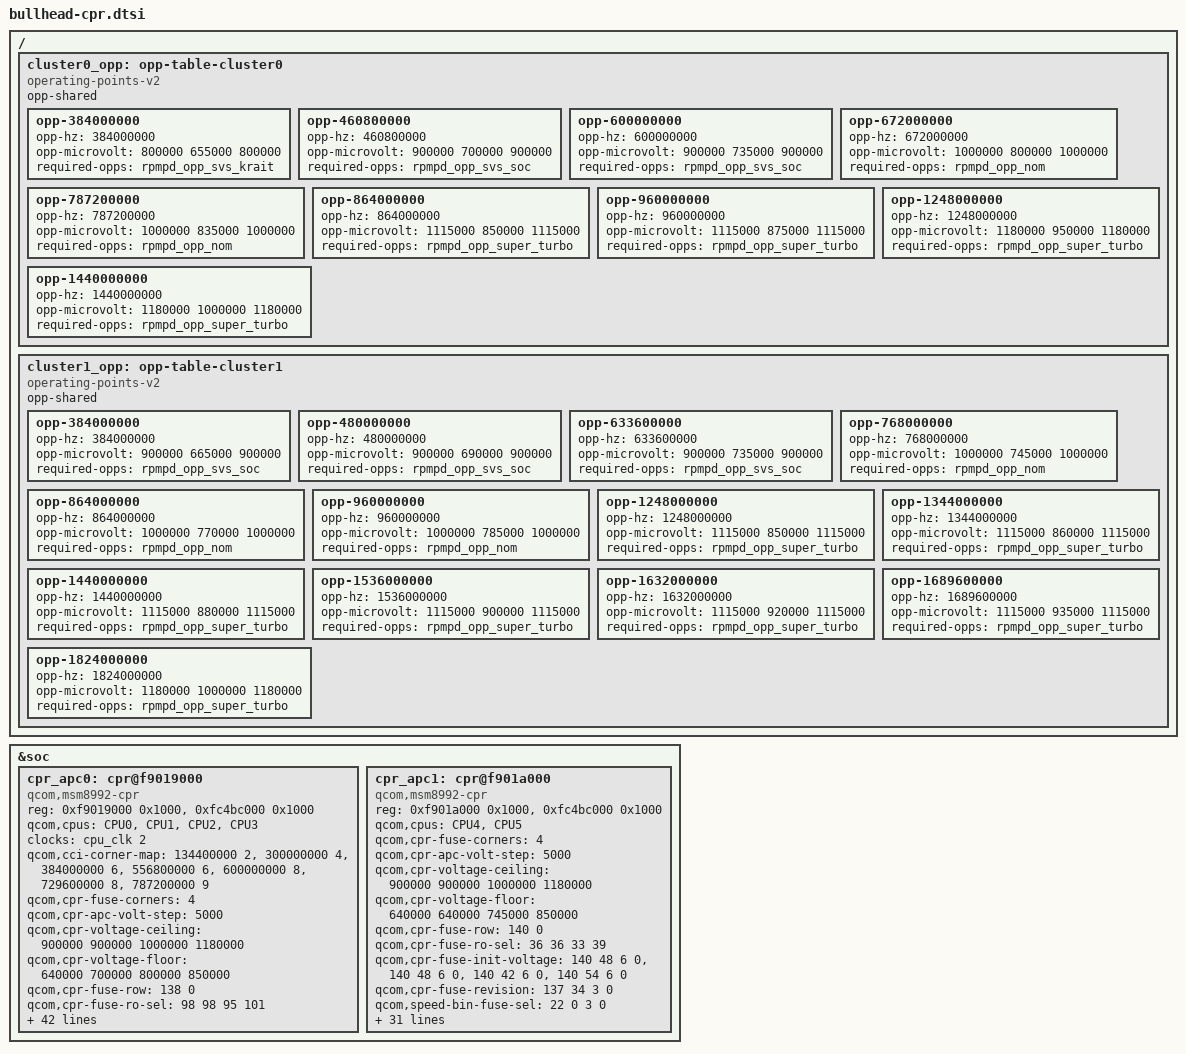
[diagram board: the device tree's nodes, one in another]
// SPDX-License-Identifier: GPL-2.0-only
/* Generated by tools/cpr/gen-cpr-dtsi.py from the 3.10 msm8992-regulator.dtsi */

&soc {
	cpr_apc0: cpr@f9019000 {
		compatible = "qcom,msm8992-cpr";
		reg = <0xf9019000 0x1000>, <0xfc4bc000 0x1000>;
		reg-names = "rbcpr", "efuse";
		qcom,cpus = <&CPU0>, <&CPU1>, <&CPU2>, <&CPU3>;
		clocks = <&cpu_clk 2>;
		clock-names = "cci";
		qcom,cci-corner-map = <134400000 2>, <300000000 4>,
			<384000000 6>, <556800000 6>, <600000000 8>,
			<729600000 8>, <787200000 9>;
		qcom,cpr-fuse-corners = <4>;
		qcom,cpr-apc-volt-step = <5000>;
		qcom,cpr-voltage-ceiling = <900000 900000 1000000 1180000>;
		qcom,cpr-voltage-floor = <640000 700000  800000  850000>;
		qcom,cpr-fuse-row = <138 0>;
		qcom,cpr-fuse-ro-sel = <98 98 95 101>;
		qcom,cpr-fuse-init-voltage = <139 46 6 0>,
			<139 46 6 0>,
			<139 40 6 0>,
			<139 52 6 0>;
		qcom,cpr-fuse-revision = <137 34 3 0>;
		qcom,speed-bin-fuse-sel = <22 56 2 0>;
		qcom,cpr-fuse-redun-sel = <62 48 3 1 0>;
		qcom,cpr-init-voltage-ref = <900000 900000 1000000 1230000>;
		qcom,cpr-init-voltage-step = <10000>;
		qcom,cpr-corner-map = <1 1 2 2 3 3 4 4 4 4>;
		qcom,cpr-voltage-ceiling-override = <0xFFFFFFFF 0  800000  800000  900000  900000
			1000000 1000000 1115000 1115000
			1180000 1180000>;
		qcom,cpr-voltage-floor-override = <0xFFFFFFFF 0  640000  655000  700000  735000
			800000  835000  850000  875000
			950000 1000000>;
		qcom,cpr-fuse-version-map = <0 0xffffffff 0 0 0 0 0>,
			<0 0xffffffff 1 0 0 0 0>,
			<0 0xffffffff 2 0 0 0 0>,
			<0 0xffffffff 3 0 0 0 0>,
			<0 0xffffffff 4 0 0 0 0>,
			<1 0xffffffff 0 0 0 0 0>,
			<1 0xffffffff 1 0 0 0 0>,
			<1 0xffffffff 2 0 0 0 0>,
			<1 0xffffffff 3 0 0 0 0>,
			<1 0xffffffff 4 0 0 0 0>;
		qcom,cpr-init-voltage-adjustment = <0 0 0 0>,
			<0 (-15000) (-35000) 35000>,
			<0 (-15000) (-35000) 35000>,
			<0 (-15000) (-25000) (-15000)>,
			<0 (-15000) (-25000) (-60000)>,
			<0 0 0 0>,
			<0 (-15000) (-35000) 95000>,
			<0 (-15000) (-35000) 95000>,
			<0 (-15000) (-25000) 45000>,
			<0 (-15000) (-25000) 0>;
		qcom,cpr-voltage-scaling-factor-max = <0 0 2000 2000>;
		qcom,cpr-corner-frequency-map = <1   300000000>,
			<2   384000000>,
			<3   460800000>,
			<4   600000000>,
			<5   672000000>,
			<6   787200000>,
			<7   864000000>,
			<8   960000000>,
			<9  1248000000>,
			<10 1440000000>;
		qcom,cpr-speed-bin-max-corners = <0 0 2 4 6 9>,
			<1 0 2 4 6 10>;
		qcom,cpr-scaled-init-voltage-as-ceiling;
	};
};

/ {
	cluster0_opp: opp-table-cluster0 {
		compatible = "operating-points-v2";
		opp-shared;

		opp-384000000 {
			opp-hz = /bits/ 64 <384000000>;
			opp-microvolt = <800000 655000 800000>;
			required-opps = <&rpmpd_opp_svs_krait>;
		};
		opp-460800000 {
			opp-hz = /bits/ 64 <460800000>;
			opp-microvolt = <900000 700000 900000>;
			required-opps = <&rpmpd_opp_svs_soc>;
		};
		opp-600000000 {
			opp-hz = /bits/ 64 <600000000>;
			opp-microvolt = <900000 735000 900000>;
			required-opps = <&rpmpd_opp_svs_soc>;
		};
		opp-672000000 {
			opp-hz = /bits/ 64 <672000000>;
			opp-microvolt = <1000000 800000 1000000>;
			required-opps = <&rpmpd_opp_nom>;
		};
		opp-787200000 {
			opp-hz = /bits/ 64 <787200000>;
			opp-microvolt = <1000000 835000 1000000>;
			required-opps = <&rpmpd_opp_nom>;
		};
		opp-864000000 {
			opp-hz = /bits/ 64 <864000000>;
			opp-microvolt = <1115000 850000 1115000>;
			required-opps = <&rpmpd_opp_super_turbo>;
		};
		opp-960000000 {
			opp-hz = /bits/ 64 <960000000>;
			opp-microvolt = <1115000 875000 1115000>;
			required-opps = <&rpmpd_opp_super_turbo>;
		};
		opp-1248000000 {
			opp-hz = /bits/ 64 <1248000000>;
			opp-microvolt = <1180000 950000 1180000>;
			required-opps = <&rpmpd_opp_super_turbo>;
		};
		opp-1440000000 {
			opp-hz = /bits/ 64 <1440000000>;
			opp-microvolt = <1180000 1000000 1180000>;
			required-opps = <&rpmpd_opp_super_turbo>;
		};
	};
};

&soc {
	cpr_apc1: cpr@f901a000 {
		compatible = "qcom,msm8992-cpr";
		reg = <0xf901a000 0x1000>, <0xfc4bc000 0x1000>;
		reg-names = "rbcpr", "efuse";
		qcom,cpus = <&CPU4>, <&CPU5>;
		qcom,cpr-fuse-corners = <4>;
		qcom,cpr-apc-volt-step = <5000>;
		qcom,cpr-voltage-ceiling = <900000 900000 1000000 1180000>;
		qcom,cpr-voltage-floor = <640000 640000  745000  850000>;
		qcom,cpr-fuse-row = <140 0>;
		qcom,cpr-fuse-ro-sel = <36 36 33 39>;
		qcom,cpr-fuse-init-voltage = <140 48 6 0>,
			<140 48 6 0>,
			<140 42 6 0>,
			<140 54 6 0>;
		qcom,cpr-fuse-revision = <137 34 3 0>;
		qcom,speed-bin-fuse-sel = <22 0 3 0>;
		qcom,cpr-fuse-redun-sel = <62 48 3 1 0>;
		qcom,cpr-init-voltage-ref = <900000 900000 1000000 1230000>;
		qcom,cpr-init-voltage-step = <10000>;
		qcom,cpr-corner-map = <1 2 2 2 2 3 3 3 4 4 4 4 4 4 4>;
		qcom,cpr-voltage-ceiling-override = <0xFFFFFFFF 0  900000  900000  900000  900000
			900000 1000000 1000000 1000000
			1115000 1115000 1115000 1115000
			1115000 1115000 1180000>;
		qcom,cpr-voltage-floor-override = <0xFFFFFFFF 0  640000  640000  665000  690000
			735000  745000  770000  785000
			850000  860000  880000  900000
			920000  935000 1000000>;
		qcom,cpr-fuse-version-map = <0xffffffff 0xffffffff 0 4 4 4 4>,
			<0xffffffff 0xffffffff 1 4 4 4 4>,
			<0xffffffff 0xffffffff 2 4 4 4 4>,
			<0xffffffff 0xffffffff 3 2 2 2 2>,
			<0xffffffff 0xffffffff 4 2 2 2 2>;
		qcom,cpr-init-voltage-adjustment = <0 0 0 0>,
			<0 0 (-25000) (-25000)>,
			<0 0 30000 (-5000)>,
			<30000 30000 (-20000) (-20000)>,
			<30000 30000 (-20000) (-20000)>;
		qcom,cpr-voltage-scaling-factor-max = <0 0 2000 2000>;
		qcom,cpr-corner-frequency-map = <1   300000000>, /* SVS Fmin for "SVS2" */
			<2   300000000>,
			<3   384000000>,
			<4   480000000>,
			<5   633600000>,
			<6   768000000>,
			<7   864000000>,
			<8   960000000>,
			<9  1248000000>,
			<10 1344000000>,
			<11 1440000000>,
			<12 1536000000>,
			<13 1632000000>,
			<14 1689600000>,
			<15 1824000000>;
		qcom,cpr-speed-bin-max-corners = <0xFFFFFFFF 0 1 5 8 15>;
		qcom,cpr-scaled-init-voltage-as-ceiling;
	};
};

/ {
	cluster1_opp: opp-table-cluster1 {
		compatible = "operating-points-v2";
		opp-shared;

		opp-384000000 {
			opp-hz = /bits/ 64 <384000000>;
			opp-microvolt = <900000 665000 900000>;
			required-opps = <&rpmpd_opp_svs_soc>;
		};
		opp-480000000 {
			opp-hz = /bits/ 64 <480000000>;
			opp-microvolt = <900000 690000 900000>;
			required-opps = <&rpmpd_opp_svs_soc>;
		};
		opp-633600000 {
			opp-hz = /bits/ 64 <633600000>;
			opp-microvolt = <900000 735000 900000>;
			required-opps = <&rpmpd_opp_svs_soc>;
		};
		opp-768000000 {
			opp-hz = /bits/ 64 <768000000>;
			opp-microvolt = <1000000 745000 1000000>;
			required-opps = <&rpmpd_opp_nom>;
		};
		opp-864000000 {
			opp-hz = /bits/ 64 <864000000>;
			opp-microvolt = <1000000 770000 1000000>;
			required-opps = <&rpmpd_opp_nom>;
		};
		opp-960000000 {
			opp-hz = /bits/ 64 <960000000>;
			opp-microvolt = <1000000 785000 1000000>;
			required-opps = <&rpmpd_opp_nom>;
		};
		opp-1248000000 {
			opp-hz = /bits/ 64 <1248000000>;
			opp-microvolt = <1115000 850000 1115000>;
			required-opps = <&rpmpd_opp_super_turbo>;
		};
		opp-1344000000 {
			opp-hz = /bits/ 64 <1344000000>;
			opp-microvolt = <1115000 860000 1115000>;
			required-opps = <&rpmpd_opp_super_turbo>;
		};
		opp-1440000000 {
			opp-hz = /bits/ 64 <1440000000>;
			opp-microvolt = <1115000 880000 1115000>;
			required-opps = <&rpmpd_opp_super_turbo>;
		};
		opp-1536000000 {
			opp-hz = /bits/ 64 <1536000000>;
			opp-microvolt = <1115000 900000 1115000>;
			required-opps = <&rpmpd_opp_super_turbo>;
		};
		opp-1632000000 {
			opp-hz = /bits/ 64 <1632000000>;
			opp-microvolt = <1115000 920000 1115000>;
			required-opps = <&rpmpd_opp_super_turbo>;
		};
		opp-1689600000 {
			opp-hz = /bits/ 64 <1689600000>;
			opp-microvolt = <1115000 935000 1115000>;
			required-opps = <&rpmpd_opp_super_turbo>;
		};
		opp-1824000000 {
			opp-hz = /bits/ 64 <1824000000>;
			opp-microvolt = <1180000 1000000 1180000>;
			required-opps = <&rpmpd_opp_super_turbo>;
		};
	};
};

